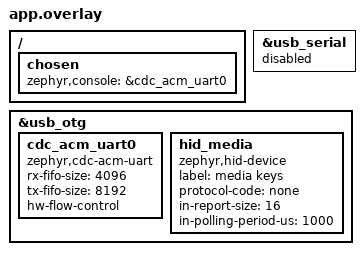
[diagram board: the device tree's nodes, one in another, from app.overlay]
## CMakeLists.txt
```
# Copyright (c) 2026 Adi Nandanamudi
# SPDX-License-Identifier: Apache-2.0

cmake_minimum_required(VERSION 3.28.0)

# This repo is a Zephyr module: board, bindings and drivers.
list(APPEND ZEPHYR_EXTRA_MODULES ${CMAKE_CURRENT_SOURCE_DIR}/../..)

find_package(Zephyr REQUIRED HINTS $ENV{ZEPHYR_BASE})
project(watch)

target_sources(app PRIVATE src/main.c src/usb_hid.c src/trace_store.c)
```

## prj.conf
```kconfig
CONFIG_IPM=y
CONFIG_I2C=y
CONFIG_RTC=y
CONFIG_INPUT=y
CONFIG_GPIO=y
CONFIG_PRINTK=y
CONFIG_LOG=y
CONFIG_SYSTEM_WORKQUEUE_STACK_SIZE=2048

# USB device (OTG): CDC-ACM console + HID media keys
CONFIG_USB_DEVICE_STACK_NEXT=y
CONFIG_USBD_CDC_ACM_CLASS=y
CONFIG_USBD_HID_SUPPORT=y
CONFIG_CDC_ACM_SERIAL_INITIALIZE_AT_BOOT=n
CONFIG_USBD_LOG_LEVEL_WRN=y
CONFIG_USBD_HID_LOG_LEVEL_WRN=y
CONFIG_USBD_CDC_ACM_LOG_LEVEL_OFF=y
CONFIG_UDC_DRIVER_LOG_LEVEL_WRN=y
CONFIG_SERIAL=y
CONFIG_UART_LINE_CTRL=y
CONFIG_REBOOT=y
CONFIG_BASE64=y
```

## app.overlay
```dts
/*
 * Copyright (c) 2026 Adi Nandanamudi
 * SPDX-License-Identifier: Apache-2.0
 *
 * Core 0: the USB-C port becomes our own USB device (the chip's USB OTG
 * controller): a CDC-ACM serial port for the console, plus a HID interface
 * that sends media keys (volume, play/pause, brightness) to the computer.
 * The OTG controller and the built-in USB-Serial-JTAG share the one PHY, so
 * the JTAG serial port is off while this runs; see src/usb_hid.c for flashing.
 */

/ {
	chosen {
		zephyr,console = &cdc_acm_uart0;
	};
};

&usb_serial {
	status = "disabled";
};

zephyr_udc0: &usb_otg {
	status = "okay";

	cdc_acm_uart0: cdc_acm_uart0 {
		compatible = "zephyr,cdc-acm-uart";
		/* a now-playing text frame is one ~3 KB line (tools/agent) */
		rx-fifo-size = <4096>;
		tx-fifo-size = <8192>; /* trace dumps are 640-byte lines in a burst */
		hw-flow-control; /* poll_out waits for room instead of dropping bytes */
	};

	hid_media: hid_media {
		compatible = "zephyr,hid-device";
		label = "media keys";
		protocol-code = "none";
		in-report-size = <16>;
		in-polling-period-us = <1000>;
	};
};
```

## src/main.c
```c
/*
 * Copyright (c) 2026 Adi Nandanamudi
 * SPDX-License-Identifier: Apache-2.0
 *
 * Watch, core 0 side: owns the RTC, touch and buttons, tells core 1 the time
 * and the button presses, and prints core 1's frame rate.
 *
 * Time: the RTC has no battery, so it loses the time when unplugged (then the
 * build time is used). Send the real time over USB with tools/settime.py: a
 * line "T YYYY-MM-DD HH:MM:SS" on the console sets the RTC. Core 1 says hello
 * when it is up; the time goes to it then (and every minute after).
 *
 * Buttons: BOOT (GPIO0, a gpio-keys input) short press, or held 3 s (face
 * picker); PWR read from the I/O expander (EXIO4, high while pressed), whose
 * interrupt line is not wired, so it is polled.
 *
 * The RTC only has 1 s resolution, so we wait for its seconds to change and
 * send the time right then: core 1 counts milliseconds from that edge, which
 * puts the gliding second hand within a few ms of the real second.
 */

#include <stdio.h>
#include <stdlib.h>
#include <string.h>
#include <zephyr/device.h>
#include <zephyr/drivers/gpio.h>
#include <zephyr/drivers/ipm.h>
#include <zephyr/drivers/rtc.h>
#include <zephyr/drivers/uart.h>
#include <zephyr/sys/base64.h>
#include <zephyr/input/input.h>
#include <zephyr/kernel.h>

#include "../common/watch_msg.h"
#include "usb_hid.h"
#include "trace_store.h"

static const struct device *const ipm = DEVICE_DT_GET(DT_NODELABEL(ipm0));
static const struct device *const rtc = DEVICE_DT_GET(DT_ALIAS(rtc));

static struct msg_stats stats;
static K_SEM_DEFINE(stats_sem, 0, 1);
static K_SEM_DEFINE(time_req, 0, 1); /* core 1 is up, or the RTC was just set */

static void on_ipm(const struct device *dev, void *user_data, uint32_t id, volatile void *data)
{
	if (id == MSG_BENCH) {
		struct msg_bench mb;

		memcpy(&mb, (const void *)data, sizeof(mb));
		if (mb.ring_full_us) {
			printk("core 1 bench: full bezel repaint %u us (%u px): bg %u ring %u hands %u"
			       " sweep %u swap %u write %u us\n", mb.ring_full_us, mb.ring_px,
			       mb.seq_read, mb.band_read, mb.compute, mb.internal_read,
			       mb.box_plain, mb.box_hands);
			return;
		}
		printk("core 1 bench (CPU cycles per pixel): flash sequential %u.%u, flash band "
		       "pattern %u.%u, internal RAM %u.%u, second-hand maths %u.%u\n",
		       mb.seq_read / 10, mb.seq_read % 10, mb.band_read / 10, mb.band_read % 10,
		       mb.internal_read / 10, mb.internal_read % 10, mb.compute / 10,
		       mb.compute % 10);
		printk("core 1 bench: render_box dial only %u.%u, with hands %u.%u cycles/px\n",
		       mb.box_plain / 10, mb.box_plain % 10, mb.box_hands / 10, mb.box_hands % 10);
		return;
	}
	if (id == MSG_TRACE) {
		trace_batch(data, TRACE_BATCH * sizeof(struct trace_ev) + 1);
		return;
	}
	if (id == MSG_KEY) {
		usb_key(((volatile struct msg_key *)data)->key);
		return;
	}
	if (id == MSG_HELLO) {
		k_sem_give(&time_req);
		return;
	}
	if (id == MSG_STATS) {
		memcpy(&stats, (const void *)data, sizeof(stats));
		k_sem_give(&stats_sem);
	}
}

static void send_button(uint8_t btn)
{
	struct msg_button mb = {.btn = btn};

	trace_rec(TR_BUTTON, btn, 0);
	int ret = msg_send(ipm, MSG_BUTTON, &mb, sizeof(mb));

	printk("button %u -> core 1 (%d)\n", btn, ret);
}

/* BOOT held for 3 s: fires once while still held */
static bool boot_long_sent;

static void boot_long(struct k_work *w)
{
	boot_long_sent = true;
	send_button(BTN_BOOT_LONG);
}
static K_WORK_DELAYABLE_DEFINE(boot_long_work, boot_long);

static void on_input(struct input_event *evt, void *user_data)
{
	static struct msg_touch t;

	if (evt->code == INPUT_KEY_0) { /* BOOT */
		if (evt->value) {
			boot_long_sent = false;
			k_work_reschedule(&boot_long_work, K_MSEC(3000));
		} else {
			k_work_cancel_delayable(&boot_long_work);
			if (!boot_long_sent) {
				send_button(BTN_BOOT);
			}
		}
		return;
	}

	if (evt->code == INPUT_ABS_MT_SLOT) {
		t.fingers = evt->value;
		return;
	}
	if (evt->code == INPUT_ABS_X) {
		t.x = evt->value;
	} else if (evt->code == INPUT_ABS_Y) {
		t.y = evt->value;
	} else if (evt->code == INPUT_BTN_TOUCH) {
		t.down = evt->value;
		if (!t.down) {
			t.fingers = 0;
		}
	}
	if (evt->sync) {
		/* Open/close the remote, once per hold: two fingers held 1.5 s, or one
		 * finger held still 2 s near the middle (away from the bezel)
		 */
		static int64_t hold_since;
		static bool hold_sent, hold_two;
		static int hx, hy;
		int dx = t.x - 233, dy = t.y - 233;
		bool middle = dx * dx + dy * dy < 120 * 120;

		if (t.down && (t.fingers >= 2 || middle)) {
			int mx = t.x - hx, my = t.y - hy;

			static int64_t last_dbg;

			if (k_uptime_get() - last_dbg > 500) { /* debug: the hold, twice a second */
				last_dbg = k_uptime_get();
				printk("hold: %lld ms, fingers %u, at %u,%u, moved %d\n",
				       hold_since ? k_uptime_get() - hold_since : 0, t.fingers, t.x, t.y,
				       mx * mx + my * my);
			}
			if (!hold_since || (t.fingers < 2 && !hold_two && mx * mx + my * my > 20 * 20)) {
				hold_since = k_uptime_get(); /* (re)start: moved too far */
				hx = t.x;
				hy = t.y;
			}
			hold_two |= t.fingers >= 2;
			if (!hold_sent && k_uptime_get() - hold_since > (hold_two ? 1500 : 2000)) {
				hold_sent = true;
				send_button(BTN_TWO_HOLD);
			}
		} else if (!t.down) {
			hold_since = 0;
			hold_sent = hold_two = false;
		}
		trace_rec(TR_TOUCH, t.down | t.fingers << 1, (t.x >> 2) << 8 | (t.y >> 2));
		msg_send(ipm, MSG_TOUCH, &t, sizeof(t));
		/* log touches (down/up and finger-count changes) */
		static uint8_t last_down, last_fingers;

		if (t.down != last_down || t.fingers != last_fingers) {
			printk("touch %s %u,%u fingers %u\n", t.down ? "down" : "up", t.x, t.y,
			       t.fingers);
			last_down = t.down;
			last_fingers = t.fingers;
		}
	}
}
INPUT_CALLBACK_DEFINE(NULL, on_input, NULL);

/* No battery: the RTC loses its time when unplugged. Fall back to the time
 * this firmware was built, so the watch is close after flashing.
 */
static void rtc_seed_from_build(void)
{
	static const char months[] = "JanFebMarAprMayJunJulAugSepOctNovDec";
	char mon[4];
	int d, y, h, m, s;
	struct rtc_time t = {0};

	sscanf(__DATE__, "%3s %d %d", mon, &d, &y);
	sscanf(__TIME__, "%d:%d:%d", &h, &m, &s);
	t.tm_year = y - 1900;
	t.tm_mon = (strstr(months, mon) - months) / 3;
	t.tm_mday = d;
	t.tm_hour = h;
	t.tm_min = m;
	t.tm_sec = s;
	rtc_set_time(rtc, &t);
	printk("RTC had no time: set from build time %s %s\n", __DATE__, __TIME__);
}

static void send_time_on_edge(void)
{
	struct rtc_time a, b;

	if (rtc_get_time(rtc, &a) != 0) {
		return;
	}
	do { /* poll until the seconds roll over */
		k_msleep(2);
		if (rtc_get_time(rtc, &b) != 0) {
			return;
		}
	} while (b.tm_sec == a.tm_sec);

	struct msg_time mt = {.year = b.tm_year + 1900, .month = b.tm_mon + 1, .day = b.tm_mday,
			      .hour = b.tm_hour, .min = b.tm_min, .sec = b.tm_sec,
			      .wday = b.tm_wday};

	trace_rec(TR_TIME_TX, 0, 0);
	msg_send(ipm, MSG_TIME, &mt, sizeof(mt));
	printk("time -> core 1: %04u-%02u-%02u %02u:%02u:%02u\n", mt.year, mt.month, mt.day,
	       mt.hour, mt.min, mt.sec);
}

/* Day of week (0 = Sunday) for the RTC, Sakamoto's method. */
static int weekday(int y, int m, int d)
{
	static const int t[] = {0, 3, 2, 5, 0, 3, 5, 1, 4, 6, 2, 4};

	y -= m < 3;
	return (y + y / 4 - y / 100 + y / 400 + t[m - 1] + d) % 7;
}

/* Console input: "T YYYY-MM-DD HH:MM:SS" sets the RTC (tools/settime.py). */
static void console_rx(void *a, void *b, void *c)
{
	const struct device *con = DEVICE_DT_GET(DT_CHOSEN(zephyr_console));
	static char line[3200]; /* "N <base64 text image>" is the longest */
	size_t n = 0;

	while (1) {
		unsigned char ch;

		if (uart_poll_in(con, &ch) != 0) {
			k_msleep(1);
			continue;
		}
		if (ch != '\n' && ch != '\r') {
			if (n < sizeof(line) - 1) {
				line[n++] = ch;
			}
			continue;
		}
		line[n] = 0;
		n = 0;
		if (line[0] == 'T' && (line[1] == '1' || line[1] == '0') && line[2] == 0) {
			if (line[1] == '1') {
				trace_start();
			} else {
				trace_stop_dump();
			}
			continue;
		}
		/* scripted actions for traces: F<face>, Z<clicks> (bezel), W<deg> (knob) */
		if ((line[0] == 'F' || line[0] == 'Z' || line[0] == 'W') && line[1]) {
			struct msg_cmd c = {.cmd = line[0] == 'F' ? CMD_FACE : line[0] == 'Z' ? CMD_BEZEL
									: CMD_KNOB,
					    .arg = (int16_t)atoi(line + 1)};

			msg_send(ipm, MSG_CMD, &c, sizeof(c));
			printk("cmd %c %d\n", line[0], c.arg);
			continue;
		}
		if (line[0] == 'B' && line[1] == 0) {
			printk("rebooting to download mode\n");
			usb_reboot_to_download();
		}
		if (line[0] == 'N' && line[1] == ' ') { /* now-playing text image, base64 */
			static uint8_t img[TEXT_BYTES + 4];
			size_t olen = 0;

			static uint32_t ok, bad, t_log;

			if (base64_decode(img, sizeof(img), &olen, (const uint8_t *)line + 2,
					  strlen(line + 2)) == 0 && olen == TEXT_BYTES) {
				static struct msg_text mt;

				for (uint16_t off = 0; off < TEXT_BYTES; off += TEXT_CHUNK) {
					mt.off = off;
					mt.len = MIN(TEXT_CHUNK, TEXT_BYTES - off);
					memcpy(mt.data, img + off, mt.len);
					msg_send(ipm, MSG_TEXT, &mt, sizeof(mt) - TEXT_CHUNK + mt.len);
				}
				trace_rec(TR_TEXT_LINE, 1, 0);
				ok++;
			} else {
				bad++;
			}
			if (k_uptime_get_32() - t_log > 2000) {
				printk("text frames: %u ok, %u bad (last %u chars)\n", ok, bad,
				       (unsigned int)strlen(line));
				ok = bad = 0;
				t_log = k_uptime_get_32();
			}
			continue;
		}
		if (line[0] == 'S' && line[1] == ' ') { /* "S v=37 m=0 b=80 p=1" from tools/agent */
			struct msg_state st = {-1, -1, -1, -1};
			char *p = line + 2;

			while (*p) {
				char k = p[0];
				int v = -1;

				if (p[1] == '=' && sscanf(p + 2, "%d", &v) == 1) {
					if (k == 'v') {
						st.volume = CLAMP(v, 0, 100);
					} else if (k == 'm') {
						st.muted = v != 0;
					} else if (k == 'b') {
						st.brightness = v < 0 ? -1 : CLAMP(v, 0, 100);
					} else if (k == 'p') {
						st.playing = v < 0 ? -1 : (v != 0);
					}
				}
				while (*p && *p != ' ') {
					p++;
				}
				while (*p == ' ') {
					p++;
				}
			}
			trace_rec(TR_HOST_STATE, (st.playing > 0) | (st.muted > 0) << 1,
				  st.volume < 0 ? 0 : st.volume);
			msg_send(ipm, MSG_STATE, &st, sizeof(st));
			continue;
		}
		if (line[0] == 'K' && line[1] >= '1' && line[1] <= '8') { /* test: send a key */
			usb_key(line[1] - '0');
			printk("key %c sent\n", line[1]);
			continue;
		}
		int y, mo, d, h, mi, s;

		if (sscanf(line, "T %d-%d-%d %d:%d:%d", &y, &mo, &d, &h, &mi, &s) != 6) {
			continue;
		}
		struct rtc_time t = {.tm_year = y - 1900, .tm_mon = mo - 1, .tm_mday = d,
				     .tm_hour = h, .tm_min = mi, .tm_sec = s,
				     .tm_wday = weekday(y, mo, d)};
		int ret = rtc_set_time(rtc, &t);

		printk("time set from USB: %04d-%02d-%02d %02d:%02d:%02d (%d)\n", y, mo, d, h, mi, s,
		       ret);
		k_sem_give(&time_req);
	}
}
K_THREAD_DEFINE(console_tid, 1536, console_rx, NULL, NULL, NULL, 6, 0, 0);

/* PWR: poll the expander every 20 ms, report presses */
static void pwr_poll(void *a, void *b, void *c)
{
	const struct device *exio = DEVICE_DT_GET(DT_NODELABEL(exio));
	bool was = false;

	if (!device_is_ready(exio) || gpio_pin_configure(exio, 4, GPIO_INPUT) != 0) {
		printk("PWR key: expander not ready\n");
		return;
	}
	while (1) {
		bool down = gpio_pin_get(exio, 4) > 0;

		if (down && !was) {
			send_button(BTN_PWR);
		}
		was = down;
		k_msleep(20);
	}
}
K_THREAD_DEFINE(pwr_tid, 1024, pwr_poll, NULL, NULL, NULL, 5, 0, 500);

int main(void)
{
	struct rtc_time t;

	int uerr = usb_start();

	k_msleep(1500); /* let the host open the serial port */
	printk("\n*** watch: core 0 *** (usb %d)\n", uerr);
	/* the panel's tearing-effect pin; core 1 polls it to pace its frames */
	gpio_pin_configure(DEVICE_DT_GET(DT_NODELABEL(gpio0)), 13, GPIO_INPUT);
	ipm_register_callback(ipm, on_ipm, NULL);
	ipm_set_enabled(ipm, 1);

	if (rtc_get_time(rtc, &t) == -ENODATA) {
		rtc_seed_from_build();
	}
	k_msleep(300);
	send_time_on_edge(); /* core 1 may not be listening yet: it says hello */

	for (int n = 1;; n++) {
		if (trace_dumping) {
			k_msleep(100); /* the dump owns the console */
			continue;
		}
		if (k_sem_take(&stats_sem, K_MSEC(2000)) == 0) {
			/* frames = frames in the last second */
			printk("core 1: %u fps, %u us/frame: %u px in %u boxes, composite %u us,"
			       " write %u us\n", stats.frames, stats.render_us, stats.px, stats.boxes,
			       stats.comp_us, stats.write_us);
			printk("   stages us: bg %u ring %u hands %u sec %u (%u px) swap %u\n",
			       stats.st_bg, stats.st_ring, stats.st_hands, stats.st_sec, stats.sec_px,
			       stats.st_swap);
			printk("   spi: %u underruns, overlap %u\n", stats.underruns, stats.overlap);
		} else {
			printk("core 1: no stats\n");
		}
		if (k_sem_take(&time_req, K_NO_WAIT) == 0 || n % 60 == 0) {
			send_time_on_edge(); /* core 1 asked, the RTC was set, or every minute */
		}
	}
	return 0;
}
```

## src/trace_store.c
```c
/*
 * Copyright (c) 2026 Adi Nandanamudi
 * SPDX-License-Identifier: Apache-2.0
 *
 * Core 0 keeps the whole trace (its RAM has room): its own events plus the
 * batches core 1 sends, in time order as they arrive. T0 prints it as
 * base64 lines of 60 events each (tools/trace/capture.py reads them).
 */

#include <string.h>
#include <zephyr/device.h>
#include <zephyr/drivers/ipm.h>
#include <zephyr/kernel.h>
#include <zephyr/sys/base64.h>
#include <zephyr/sys/printk.h>
#include <zephyr/drivers/uart.h>

#include "../common/watch_msg.h"
#include "trace_store.h"

#define TRACE_MAX 16384 /* events: 128 KB, about 2 s of busy GMT frames */

static struct trace_ev store[TRACE_MAX];
static volatile int n_ev;
static volatile bool on;
volatile bool trace_dumping; /* main.c pauses its stats lines meanwhile */
static int dropped;

static const struct device *const ipm_dev = DEVICE_DT_GET(DT_NODELABEL(ipm0));

void trace_rec(uint8_t ev, uint8_t a, uint16_t b)
{
	if (!on) {
		return;
	}
	uint32_t key = irq_lock();

	if (n_ev < TRACE_MAX) {
		store[n_ev++] = (struct trace_ev){.ts = trace_now(), .ev = ev, .a = a, .b = b};
	} else {
		dropped++;
	}
	irq_unlock(key);
}

void trace_batch(const volatile void *msg, int len)
{
	const volatile struct msg_trace *m = msg;
	int n = m->n;

	if (!on || n > TRACE_BATCH || len < 1 + n * (int)sizeof(struct trace_ev)) {
		return;
	}
	uint32_t key = irq_lock();

	if (n_ev + n <= TRACE_MAX) {
		memcpy(&store[n_ev], (const void *)m->ev, n * sizeof(struct trace_ev));
		n_ev += n;
	} else {
		dropped += n;
	}
	irq_unlock(key);
}

static void ctl(bool enable)
{
	struct msg_trace_ctl c = {.on = enable};

	msg_send(ipm_dev, MSG_TRACE_CTL, &c, sizeof(c));
}

void trace_start(void)
{
	n_ev = 0;
	dropped = 0;
	on = true;
	trace_rec(TR_TRACE_ON, 0, 0);
	ctl(true);
	systimer_ll_counter_snapshot(&SYSTIMER, 1);
	printk("TR start now u0=%u u1=%u\n", trace_now(),
	       systimer_ll_get_counter_value_low(&SYSTIMER, 1));
}

/* straight to the console port: printk goes through the log buffer, which
 * drops lines when a dump floods it
 */
static void out(const char *str)
{
	const struct device *con = DEVICE_DT_GET(DT_CHOSEN(zephyr_console));

	for (; *str; str++) {
		uart_poll_out(con, *str);
	}
}

void trace_stop_dump(void)
{
	ctl(false);
	k_msleep(50); /* core 1 flushes its last batch between frames */
	on = false;
	trace_dumping = true;
	k_msleep(20); /* a stats line in progress finishes */
	int n = n_ev;
	static char line[TRACE_BATCH * sizeof(struct trace_ev) * 4 / 3 + 8];

	snprintk(line, sizeof(line), "TR begin %d %d %u\n", n, dropped, TRACE_HZ);
	out(line);
	for (int i = 0; i < n; i += TRACE_BATCH) {
		int k = MIN(TRACE_BATCH, n - i);
		size_t olen;

		base64_encode((uint8_t *)line, sizeof(line), &olen, (const uint8_t *)&store[i],
			      k * sizeof(struct trace_ev));
		line[olen] = '\n';
		line[olen + 1] = 0;
		out("TR ");
		out(line);
	}
	out("TR end\n");
	trace_dumping = false;
}
```

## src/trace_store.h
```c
/*
 * Copyright (c) 2026 Adi Nandanamudi
 * SPDX-License-Identifier: Apache-2.0
 */
#pragma once

#include <stdbool.h>
#include <stdint.h>
#include "../common/trace.h"

extern volatile bool trace_dumping;
void trace_rec(uint8_t ev, uint8_t a, uint16_t b);   /* a core 0 event */
void trace_batch(const volatile void *msg, int len);  /* MSG_TRACE from core 1 (ISR) */
void trace_start(void);                               /* T1: clear, tell core 1 */
void trace_stop_dump(void);                           /* T0: tell core 1, print */
```

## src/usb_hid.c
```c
/*
 * Copyright (c) 2026 Adi Nandanamudi
 * SPDX-License-Identifier: Apache-2.0
 *
 * Core 0: the USB device. One USB-C port, two interfaces:
 *   - CDC-ACM serial: the console (logs, tools/settime.py)
 *   - HID: media keys for the computer, sent when core 1 asks (MSG_KEY)
 *
 * Keys: volume up/down, mute and play/pause are standard Consumer Control
 * usages that Windows and macOS act on with no app; so are Consumer "Display
 * Brightness Increment/Decrement". (No keyboard report: a HID keyboard makes
 * macOS open its Keyboard Setup Assistant every time the watch is plugged in.)
 *
 * The chip's USB-Serial-JTAG (the usual flashing port) shares the PHY with
 * the OTG controller used here, so it is off while this runs. A console line
 * "B" reboots into the ROM's download mode (USB-Serial-JTAG again), so
 * west flash works without touching the buttons (tools/flash.sh).
 */

#include <zephyr/device.h>
#include <zephyr/kernel.h>
#include <zephyr/sys/printk.h>
#include <zephyr/sys/reboot.h>
#include <zephyr/usb/usbd.h>
#include <zephyr/usb/class/usbd_hid.h>
#include <soc/rtc_cntl_reg.h>

#include "../common/watch_msg.h"
#include "usb_hid.h"
#include "trace_store.h"

#define REPORT_CONSUMER 1

static const uint8_t report_desc[] = {
	/* Consumer Control: one 16-bit usage */
	0x05, 0x0C,       /* Usage Page (Consumer) */
	0x09, 0x01,       /* Usage (Consumer Control) */
	0xA1, 0x01,       /* Collection (Application) */
	0x85, REPORT_CONSUMER,
	0x15, 0x00,       /*   Logical Minimum (0) */
	0x26, 0xFF, 0x03, /*   Logical Maximum (0x3FF) */
	0x19, 0x00,       /*   Usage Minimum (0) */
	0x2A, 0xFF, 0x03, /*   Usage Maximum (0x3FF) */
	0x75, 0x10,       /*   Report Size (16) */
	0x95, 0x01,       /*   Report Count (1) */
	0x81, 0x00,       /*   Input (Data, Array) */
	0xC0,             /* End Collection */

};

/* Consumer usages and keyboard keys per MSG_KEY code */
static const struct {
	uint16_t consumer;
} keymap[] = {
	[KEY_VOL_UP] = {0x00E9},
	[KEY_VOL_DOWN] = {0x00EA},
	[KEY_MUTE] = {0x00E2},
	[KEY_PLAY_PAUSE] = {0x00CD},
	[KEY_BRIGHT_UP] = {0x006F},
	[KEY_BRIGHT_DOWN] = {0x0070},
	[KEY_NEXT] = {0x00B5}, /* Scan Next Track */
	[KEY_PREV] = {0x00B6}, /* Scan Previous Track */
};

static const struct device *const hid_dev = DEVICE_DT_GET(DT_NODELABEL(hid_media));
static K_SEM_DEFINE(report_done, 1, 1);
static bool hid_ready;
K_MSGQ_DEFINE(key_q, sizeof(uint8_t), 16, 1);

static void iface_ready(const struct device *dev, const bool ready)
{
	hid_ready = ready;
}

static void input_report_done(const struct device *dev, const uint8_t *const report)
{
	k_sem_give(&report_done);
}

static int get_report(const struct device *dev, const uint8_t type, const uint8_t id,
		      const uint16_t len, uint8_t *const buf)
{
	return 0;
}

static const struct hid_device_ops hid_ops = {
	.iface_ready = iface_ready,
	.get_report = get_report,
	.input_report_done = input_report_done,
};

/* one report at a time; the stack keeps the buffer until it is sent */
static uint8_t report[8] __aligned(4);

static void send(const uint8_t *r, size_t len)
{
	if (!hid_ready || k_sem_take(&report_done, K_MSEC(50)) != 0) {
		return;
	}
	memcpy(report, r, len);
	if (hid_device_submit_report(hid_dev, len, report) != 0) {
		k_sem_give(&report_done);
	}
}

static void key_thread(void *a, void *b, void *c)
{
	uint8_t k;

	while (1) {
		k_msgq_get(&key_q, &k, K_FOREVER);
		if (k == 0 || k >= ARRAY_SIZE(keymap)) {
			continue;
		}
		uint16_t u = keymap[k].consumer;

		trace_rec(TR_HID_KEY, k, hid_ready);
		printk("hid key %u (usage 0x%02x)%s\n", k, u, hid_ready ? "" : " - host not ready");
		const uint8_t press[] = {REPORT_CONSUMER, u & 0xff, u >> 8};
		const uint8_t release[] = {REPORT_CONSUMER, 0, 0};

		send(press, sizeof(press));
		k_msleep(12);
		send(release, sizeof(release));
		k_msleep(4);
	}
}
K_THREAD_DEFINE(key_tid, 1024, key_thread, NULL, NULL, NULL, 4, 0, 0);

void usb_key(uint8_t key)
{
	(void)k_msgq_put(&key_q, &key, K_NO_WAIT);
}

/* ---- device setup ---------------------------------------------------------------------- */

/* pid.codes test VID/PID: fine on your own desk, not for products */
USBD_DEVICE_DEFINE(watch_usbd, DEVICE_DT_GET(DT_NODELABEL(zephyr_udc0)), 0x1209, 0x0001);
USBD_DESC_LANG_DEFINE(watch_lang);
USBD_DESC_MANUFACTURER_DEFINE(watch_mfr, "Zephyr watch");
USBD_DESC_PRODUCT_DEFINE(watch_product, "AMOLED watch remote");
USBD_DESC_CONFIG_DEFINE(watch_cfg_desc, "FS Configuration");
USBD_CONFIGURATION_DEFINE(watch_config, 0, 250, &watch_cfg_desc);

int usb_start(void)
{
	int err;

	err = hid_device_register(hid_dev, report_desc, sizeof(report_desc), &hid_ops);
	if (err) {
		return err;
	}
	err = usbd_add_descriptor(&watch_usbd, &watch_lang);
	err = err ?: usbd_add_descriptor(&watch_usbd, &watch_mfr);
	err = err ?: usbd_add_descriptor(&watch_usbd, &watch_product);
	err = err ?: usbd_add_configuration(&watch_usbd, USBD_SPEED_FS, &watch_config);
	err = err ?: usbd_register_all_classes(&watch_usbd, USBD_SPEED_FS, 1, NULL);
	if (err) {
		return err;
	}
	/* CDC-ACM has two interfaces: say so with the IAD class triple */
	usbd_device_set_code_triple(&watch_usbd, USBD_SPEED_FS, USB_BCC_MISCELLANEOUS, 0x02, 0x01);
	err = usbd_init(&watch_usbd);
	return err ?: usbd_enable(&watch_usbd);
}

/* Reboot into the ROM download mode on USB-Serial-JTAG (for flashing). */
void usb_reboot_to_download(void)
{
	usbd_disable(&watch_usbd);
	k_msleep(50);
	/* PHY back to USB-Serial-JTAG, and ask the ROM to stay in download mode */
	REG_CLR_BIT(RTC_CNTL_USB_CONF_REG, RTC_CNTL_SW_HW_USB_PHY_SEL);
	REG_WRITE(RTC_CNTL_OPTION1_REG, RTC_CNTL_FORCE_DOWNLOAD_BOOT);
	sys_reboot(SYS_REBOOT_COLD);
}
```

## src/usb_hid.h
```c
/*
 * Copyright (c) 2026 Adi Nandanamudi
 * SPDX-License-Identifier: Apache-2.0
 */
#pragma once

#include <stdint.h>

int usb_start(void);                /* CDC-ACM console + HID media keys */
void usb_key(uint8_t key);          /* queue a KEY_* press for the computer */
void usb_reboot_to_download(void);  /* for flashing: ROM download mode */
```
